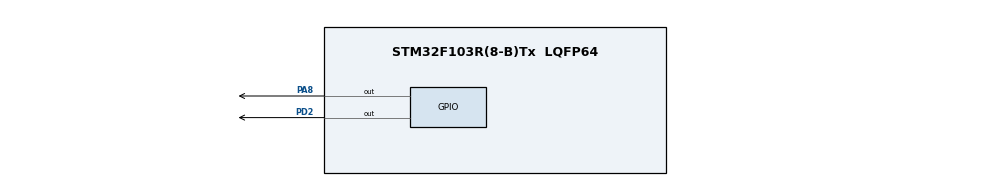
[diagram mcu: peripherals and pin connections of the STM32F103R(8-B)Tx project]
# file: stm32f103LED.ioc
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Mcu.Family=STM32F1
Mcu.Name=STM32F103R(8-B)Tx
Mcu.Package=LQFP64
NVIC.PriorityGroup=NVIC_PRIORITYGROUP_4
PA8.GPIO_Speed=GPIO_SPEED_FREQ_HIGH
PA8.PinState=GPIO_PIN_SET
PA8.Signal=GPIO_Output
PD0-OSC_IN.Mode=HSE-External-Oscillator
PD0-OSC_IN.Signal=RCC_OSC_IN
PD1-OSC_OUT.Mode=HSE-External-Oscillator
PD1-OSC_OUT.Signal=RCC_OSC_OUT
PD2.GPIO_Speed=GPIO_SPEED_FREQ_HIGH
PD2.PinState=GPIO_PIN_SET
PD2.Signal=GPIO_Output
ProjectManager.HeapSize=0x200
ProjectManager.StackSize=0x400
ProjectManager.TargetToolchain=MDK-ARM V5
RCC.APB1Freq_Value=8000000
RCC.APB2Freq_Value=8000000
RCC.SYSCLKSource=RCC_SYSCLKSOURCE_HSE
board=stm32f103LED

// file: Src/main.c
/**
  ******************************************************************************
  * File Name          : main.c
  * Description        : Main program body
  ******************************************************************************
  *
  * COPYRIGHT(c) 2019 STMicroelectronics
  *
  * Redistribution and use in source and binary forms, with or without modification,
  * are permitted provided that the following conditions are met:
  *   1. Redistributions of source code must retain the above copyright notice,
  *      this list of conditions and the following disclaimer.
  *   2. Redistributions in binary form must reproduce the above copyright notice,
  *      this list of conditions and the following disclaimer in the documentation
  *      and/or other materials provided with the distribution.
  *   3. Neither the name of STMicroelectronics nor the names of its contributors
  *      may be used to endorse or promote products derived from this software
  *      without specific prior written permission.
  *
  * THIS SOFTWARE IS PROVIDED BY THE COPYRIGHT HOLDERS AND CONTRIBUTORS "AS IS"
  * AND ANY EXPRESS OR IMPLIED WARRANTIES, INCLUDING, BUT NOT LIMITED TO, THE
  * IMPLIED WARRANTIES OF MERCHANTABILITY AND FITNESS FOR A PARTICULAR PURPOSE ARE
  * DISCLAIMED. IN NO EVENT SHALL THE COPYRIGHT HOLDER OR CONTRIBUTORS BE LIABLE
  * FOR ANY DIRECT, INDIRECT, INCIDENTAL, SPECIAL, EXEMPLARY, OR CONSEQUENTIAL
  * DAMAGES (INCLUDING, BUT NOT LIMITED TO, PROCUREMENT OF SUBSTITUTE GOODS OR
  * SERVICES; LOSS OF USE, DATA, OR PROFITS; OR BUSINESS INTERRUPTION) HOWEVER
  * CAUSED AND ON ANY THEORY OF LIABILITY, WHETHER IN CONTRACT, STRICT LIABILITY,
  * OR TORT (INCLUDING NEGLIGENCE OR OTHERWISE) ARISING IN ANY WAY OUT OF THE USE
  * OF THIS SOFTWARE, EVEN IF ADVISED OF THE POSSIBILITY OF SUCH DAMAGE.
  *
  ******************************************************************************
  */
#include "stm32f1xx_hal.h"

/* USER CODE BEGIN PV */
/* Private variables ---------------------------------------------------------*/

/* USER CODE END PV */

void SystemClock_Config(void);
static void MX_GPIO_Init(void);

/* USER CODE BEGIN PFP */
/* Private function prototypes -----------------------------------------------*/

/* USER CODE END PFP */

/* USER CODE BEGIN 0 */
void Delay(__IO uint32_t nCount);
void Delay(__IO uint32_t nCount)
{
	while(nCount--){}
}

/* USER CODE END 0 */

int main(void)
{

  /* MCU Configuration----------------------------------------------------------*/

  /* Reset of all peripherals, Initializes the Flash interface and the Systick. */
  HAL_Init();

  /* Configure the system clock */
  SystemClock_Config();

  /* Initialize all configured peripherals */
  MX_GPIO_Init();

  /* Infinite loop */
  /* USER CODE BEGIN WHILE */
  while (1)
  {
		HAL_GPIO_WritePin(GPIOA,GPIO_PIN_8,GPIO_PIN_SET); //PA8
		HAL_GPIO_WritePin(GPIOD,GPIO_PIN_2,GPIO_PIN_SET); //PD2
		Delay(0x7FFFFF);
		HAL_GPIO_WritePin(GPIOA,GPIO_PIN_8,GPIO_PIN_RESET); //PA8
		HAL_GPIO_WritePin(GPIOD,GPIO_PIN_2,GPIO_PIN_RESET); //PD2
		Delay(0x7FFFFF);

  /* USER CODE END WHILE */

  }

}

/** System Clock Configuration
*/
void SystemClock_Config(void)
{

  RCC_OscInitTypeDef RCC_OscInitStruct;
  RCC_ClkInitTypeDef RCC_ClkInitStruct;

  RCC_OscInitStruct.OscillatorType = RCC_OSCILLATORTYPE_HSE;
  RCC_OscInitStruct.HSEState = RCC_HSE_ON;
  RCC_OscInitStruct.PLL.PLLState = RCC_PLL_NONE;
  HAL_RCC_OscConfig(&RCC_OscInitStruct);

  RCC_ClkInitStruct.ClockType = RCC_CLOCKTYPE_HCLK|RCC_CLOCKTYPE_SYSCLK
                              |RCC_CLOCKTYPE_PCLK1|RCC_CLOCKTYPE_PCLK2;
  RCC_ClkInitStruct.SYSCLKSource = RCC_SYSCLKSOURCE_HSE;
  RCC_ClkInitStruct.AHBCLKDivider = RCC_SYSCLK_DIV1;
  RCC_ClkInitStruct.APB1CLKDivider = RCC_HCLK_DIV1;
  RCC_ClkInitStruct.APB2CLKDivider = RCC_HCLK_DIV1;
  HAL_RCC_ClockConfig(&RCC_ClkInitStruct, FLASH_LATENCY_0);

  HAL_SYSTICK_Config(HAL_RCC_GetHCLKFreq()/1000);

  HAL_SYSTICK_CLKSourceConfig(SYSTICK_CLKSOURCE_HCLK);

  /* SysTick_IRQn interrupt configuration */
  HAL_NVIC_SetPriority(SysTick_IRQn, 0, 0);
}

/** Configure pins as
        * Analog
        * Input
        * Output
        * EVENT_OUT
        * EXTI
*/
void MX_GPIO_Init(void)
{

  GPIO_InitTypeDef GPIO_InitStruct;

  /* GPIO Ports Clock Enable */
  __HAL_RCC_GPIOD_CLK_ENABLE();
  __HAL_RCC_GPIOA_CLK_ENABLE();

  /*Configure GPIO pin Output Level */
  HAL_GPIO_WritePin(GPIOA, GPIO_PIN_8, GPIO_PIN_SET);

  /*Configure GPIO pin Output Level */
  HAL_GPIO_WritePin(GPIOD, GPIO_PIN_2, GPIO_PIN_SET);

  /*Configure GPIO pin : PA8 */
  GPIO_InitStruct.Pin = GPIO_PIN_8;
  GPIO_InitStruct.Mode = GPIO_MODE_OUTPUT_PP;
  GPIO_InitStruct.Speed = GPIO_SPEED_FREQ_HIGH;
  HAL_GPIO_Init(GPIOA, &GPIO_InitStruct);

  /*Configure GPIO pin : PD2 */
  GPIO_InitStruct.Pin = GPIO_PIN_2;
  GPIO_InitStruct.Mode = GPIO_MODE_OUTPUT_PP;
  GPIO_InitStruct.Speed = GPIO_SPEED_FREQ_HIGH;
  HAL_GPIO_Init(GPIOD, &GPIO_InitStruct);

}

/************************ (C) COPYRIGHT STMicroelectronics *****END OF FILE****/
